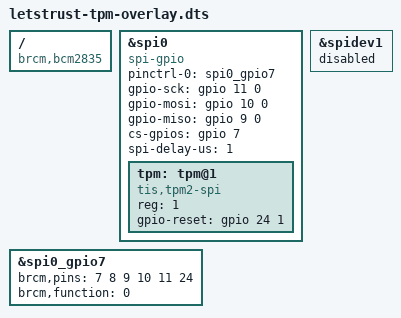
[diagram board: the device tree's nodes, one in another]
/dts-v1/; /plugin/;

/ {
    compatible = "brcm,bcm2835", "brcm,bcm2708", "brcm,bcm2709";

    fragment@0 {
        target = <&spi0>;
        __overlay__ {
            compatible = "spi-gpio";
            pinctrl-names = "default";
            pinctrl-0 = <&spi0_gpio7>;
            gpio-sck = <&gpio 11 0>;
            gpio-mosi = <&gpio 10 0>;
            gpio-miso = <&gpio 9 0>;
            cs-gpios = <&gpio 7 0>;
            spi-delay-us = <1>;
            #address-cells = <1>;
            #size-cells = <0>;
            status = "okay";

            tpm: tpm@1 {
                compatible = "tis,tpm2-spi", "infineon,slb9670";
                reg = <1>;
                gpio-reset = <&gpio 24 1>;
                #address-cells = <1>;
                #size-cells = <0>;
                status = "okay";

            };
        };
    };

    fragment@1 {
        target = <&spi0_gpio7>;
        __overlay__ {
            brcm,pins = <7 8 9 10 11 24>;
            brcm,function = <0>;
        };
    };

    fragment@2 {
        target = <&spidev1>;
        __overlay__ {
            status = "disabled";
        };
    };
};
